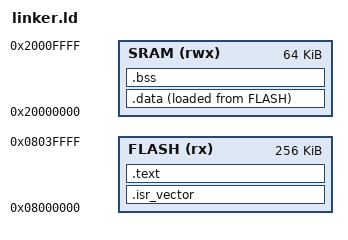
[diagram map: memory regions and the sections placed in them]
MEMORY
{
    FLASH (rx)  : ORIGIN = 0x08000000, LENGTH = 256K
    SRAM  (rwx) : ORIGIN = 0x20000000, LENGTH = 64K
}

_stack_top = ORIGIN(SRAM) + LENGTH(SRAM);

SECTIONS
{
    .isr_vector :
    {
        KEEP(*(.isr_vector))
    } > FLASH

    .text :
    {
        *(.text*)
        *(.rodata*)
        . = ALIGN(4);
    } > FLASH

    _etext = .;

    .data :
    {
        _sdata = .;
        *(.data*)
        . = ALIGN(4);
        _edata = .;
    } > SRAM AT> FLASH

    _sidata = LOADADDR(.data);

    .bss (NOLOAD) :
    {
        _sbss = .;
        *(.bss*)
        *(COMMON)
        . = ALIGN(4);
        _ebss = .;
    } > SRAM

    _end = .;
}
